# STM32F103ZGT7 register map
File version: 1.0
Registers are 32-bit, access not given, reset 0x0 unless marked. A register's access mark holds for its fields unless they carry their own. Offsets are from the block's base; [hi:lo] are bit positions; {n}, {i} and the like mark numbered series; 'fields as' and 'values as' point back to an identical list.

## RCC
Base 0x40021000
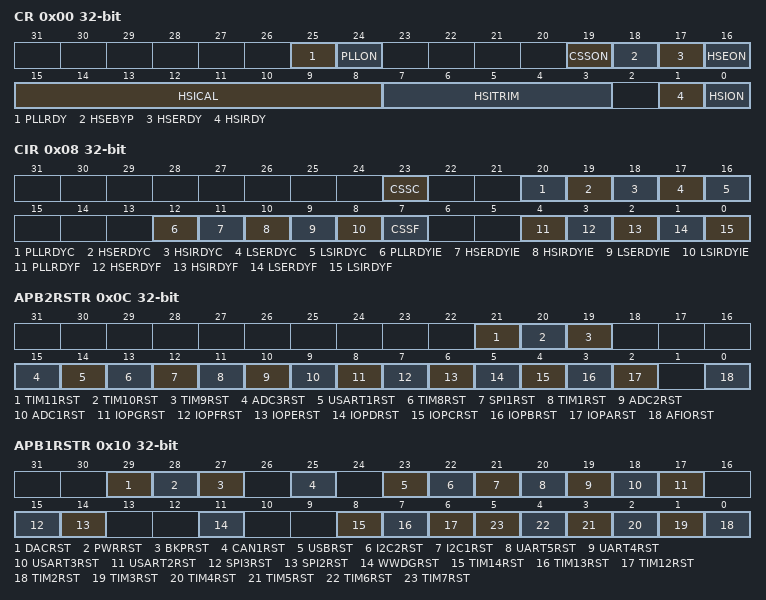
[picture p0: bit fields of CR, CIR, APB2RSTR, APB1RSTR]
0x00 CR
  [25] PLLRDY, [24] PLLON, [19] CSSON, [18] HSEBYP, [17] HSERDY, [16] HSEON, [15:8] HSICAL, [7:3] HSITRIM, [1] HSIRDY, [0] HSION
0x04 CFGR
  [26:24] MCO, [22] USBPRE, [21] PLLMULL10, [20] PLLMULL6, [20:19] PLLMULL8, [20:18] PLLMULL9, [17] PLLXTPRE, [16] PLLSRC, [15:14] ADCPRE, [13:11] PPRE2, [10:8] PPRE1, [7:4] HPRE, [3:2] SWS, [1:0] SW
0x08 CIR
  [23] CSSC, [20] PLLRDYC, [19] HSERDYC, [18] HSIRDYC, [17] LSERDYC, [16] LSIRDYC, [12] PLLRDYIE, [11] HSERDYIE, [10] HSIRDYIE, [9] LSERDYIE, [8] LSIRDYIE, [7] CSSF, [4] PLLRDYF, [3] HSERDYF, [2] HSIRDYF, [1] LSERDYF, [0] LSIRDYF
0x0C APB2RSTR
  [21] TIM11RST, [20] TIM10RST, [19] TIM9RST, [15] ADC3RST, [14] USART1RST, [13] TIM8RST, [12] SPI1RST, [11] TIM1RST, [10] ADC2RST, [9] ADC1RST, [8] IOPGRST, [7] IOPFRST, [6] IOPERST, [5] IOPDRST, [4] IOPCRST, [3] IOPBRST, [2] IOPARST, [0] AFIORST
0x10 APB1RSTR
  [29] DACRST, [28] PWRRST, [27] BKPRST, [25] CAN1RST, [23] USBRST, [22] I2C2RST, [21] I2C1RST, [20] UART5RST, [19] UART4RST, [18] USART3RST, [17] USART2RST, [15] SPI3RST, [14] SPI2RST, [11] WWDGRST, [8] TIM14RST, [7] TIM13RST, [6] TIM12RST, [n-2] TIM{n}RST (n=2..7)
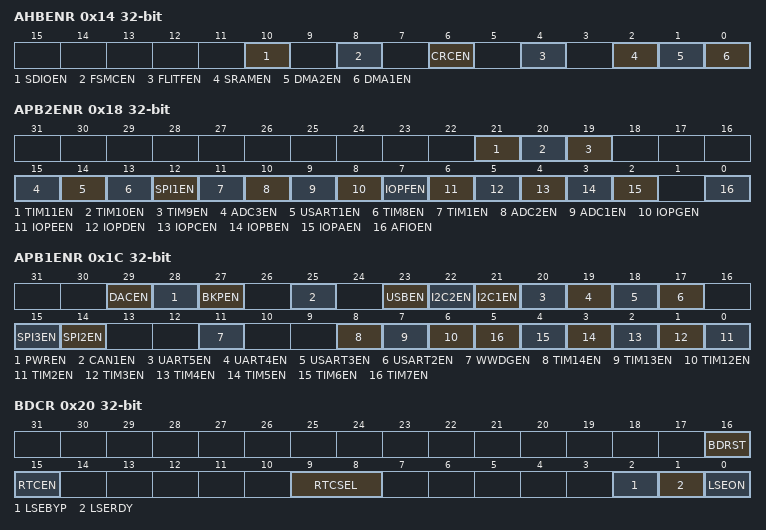
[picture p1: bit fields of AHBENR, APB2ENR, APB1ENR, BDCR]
0x14 AHBENR
  [10] SDIOEN, [8] FSMCEN, [6] CRCEN, [4] FLITFEN, [2] SRAMEN, [1] DMA2EN, [0] DMA1EN
0x18 APB2ENR
  [21] TIM11EN, [20] TIM10EN, [19] TIM9EN, [15] ADC3EN, [14] USART1EN, [13] TIM8EN, [12] SPI1EN, [11] TIM1EN, [10] ADC2EN, [9] ADC1EN, [8] IOPGEN, [7] IOPFEN, [6] IOPEEN, [5] IOPDEN, [4] IOPCEN, [3] IOPBEN, [2] IOPAEN, [0] AFIOEN
0x1C APB1ENR
  [29] DACEN, [28] PWREN, [27] BKPEN, [25] CAN1EN, [23] USBEN, [22] I2C2EN, [21] I2C1EN, [20] UART5EN, [19] UART4EN, [18] USART3EN, [17] USART2EN, [15] SPI3EN, [14] SPI2EN, [11] WWDGEN, [8] TIM14EN, [7] TIM13EN, [6] TIM12EN, [n-2] TIM{n}EN (n=2..7)
0x20 BDCR
  [16] BDRST, [15] RTCEN, [9:8] RTCSEL, [2] LSEBYP, [1] LSERDY, [0] LSEON
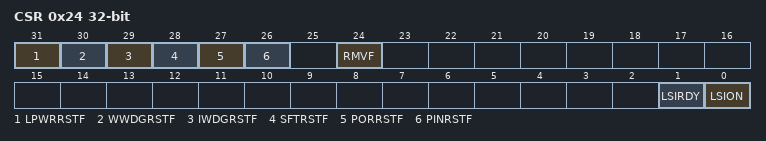
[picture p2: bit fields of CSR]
0x24 CSR
  [31] LPWRRSTF, [30] WWDGRSTF, [29] IWDGRSTF, [28] SFTRSTF, [27] PORRSTF, [26] PINRSTF, [24] RMVF, [1] LSIRDY, [0] LSION

## FLASH
Base 0x40022000
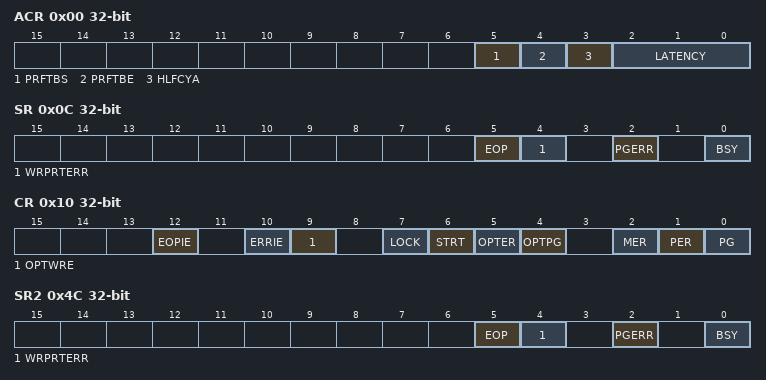
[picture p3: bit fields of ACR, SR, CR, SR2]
0x00 ACR
  [5] PRFTBS, [4] PRFTBE, [3] HLFCYA, [2:0] LATENCY
0x04 KEYR
  [31:0] FKEYR
0x08 OPTKEYR
  [31:0] OPTKEYR2
0x0C SR
  [5] EOP, [4] WRPRTERR, [2] PGERR, [0] BSY
0x10 CR
  [12] EOPIE, [10] ERRIE, [9] OPTWRE, [7] LOCK, [6] STRT, [5] OPTER, [4] OPTPG, [2] MER, [1] PER, [0] PG
0x14 AR
  [31:0] FAR2
0x1C OBR
  [25:18] DATA1, [17:10] DATA0, [5] BFB2, [4] nRST_STDBY, [3] nRST_STOP, [5:2] USER, [1] RDPRT, [0] OPTERR
0x20 WRPR
  [31:0] WRP
0x44 KEYR2
0x4C SR2
  [5] EOP, [4] WRPRTERR, [2] PGERR, [0] BSY
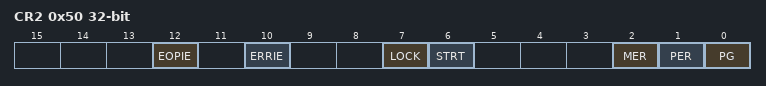
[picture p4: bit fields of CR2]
0x50 CR2
  [12] EOPIE, [10] ERRIE, [7] LOCK, [6] STRT, [2] MER, [1] PER, [0] PG
0x54 AR2

## CRC
Base 0x40023000
0x00 DR
0x04 IDR 8-bit
0x08 CR
  [0] RESET

## FSMC_Bank1
Base 0xA0000000
0x00 BTCR.0
  [29:28] ACCMOD, [27:24] DATLAT, [23:20] CLKDIV, [19] CBURSTRW, [19:16] BUSTURN, [15] ASYNCWAIT, [14] EXTMOD, [13] WAITEN, [12] WREN, [11] WAITCFG, [10] WRAPMOD, [9] WAITPOL, [15:8] DATAST, [6] FACCEN, [5:4] MWID, [3:2] MTYP, [1] MUXEN, [0] MBKEN
0x04 BTCR.1
  fields as BTCR.0
0x08 BTCR.2
  fields as BTCR.0
0x0C BTCR.3
  fields as BTCR.0
0x10 BTCR.4
  fields as BTCR.0
0x14 BTCR.5
  fields as BTCR.0
0x18 BTCR.6
  fields as BTCR.0
0x1C BTCR.7
  fields as BTCR.0

## FSMC_Bank2_3
Base 0xA0000060
0x00 PCR2
0x04 SR2
0x08 PMEM2
0x0C PATT2
0x14 ECCR2
  [31:0] ECC2
0x20 PCR3
0x24 SR3
0x28 PMEM3
0x2C PATT3
0x34 ECCR3
  [31:0] ECC3

## FSMC_Bank4
Base 0xA00000A0
0x00 PCR4
0x04 SR4
0x08 PMEM4
0x0C PATT4
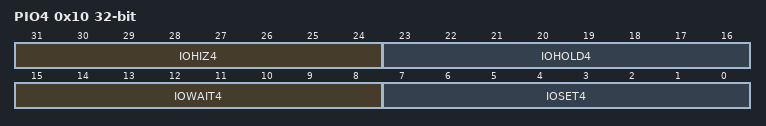
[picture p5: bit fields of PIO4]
0x10 PIO4
  [31:24] IOHIZ4, [23:16] IOHOLD4, [15:8] IOWAIT4, [7:0] IOSET4

## FSMC_Bank1E
Base 0xA0000104
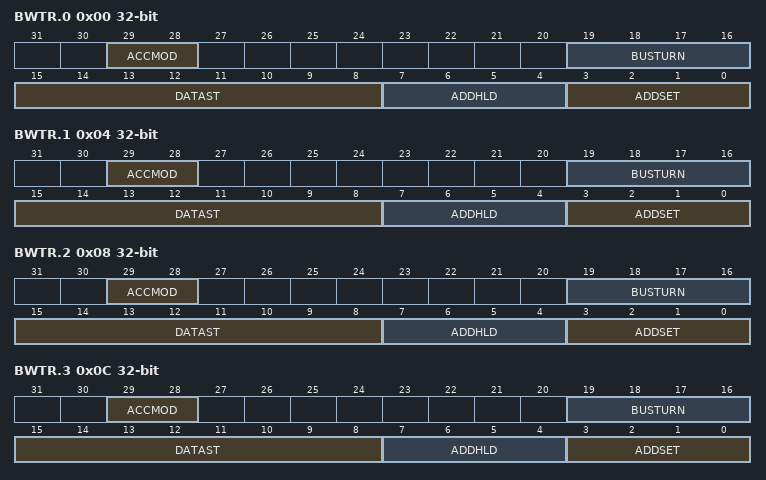
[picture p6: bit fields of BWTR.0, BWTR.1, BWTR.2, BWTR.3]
0x00 BWTR.0
  [29:28] ACCMOD, [19:16] BUSTURN, [15:8] DATAST, [7:4] ADDHLD, [3:0] ADDSET
0x04 BWTR.1
  fields as BWTR.0
0x08 BWTR.2
  fields as BWTR.0
0x0C BWTR.3
  fields as BWTR.0
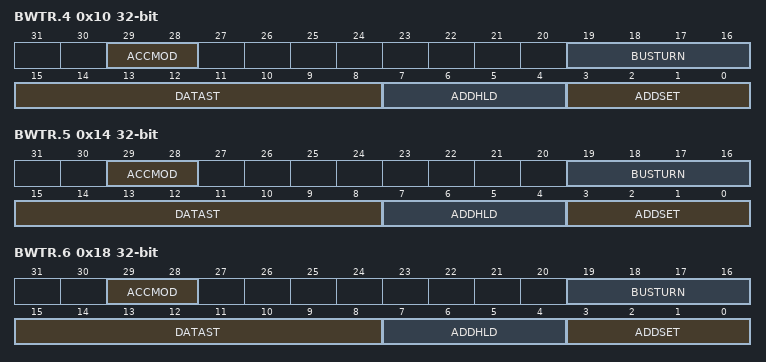
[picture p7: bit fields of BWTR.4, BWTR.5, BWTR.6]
0x10 BWTR.4
  fields as BWTR.0
0x14 BWTR.5
  fields as BWTR.0
0x18 BWTR.6
  fields as BWTR.0

## DBGMCU
Base 0xE0042000
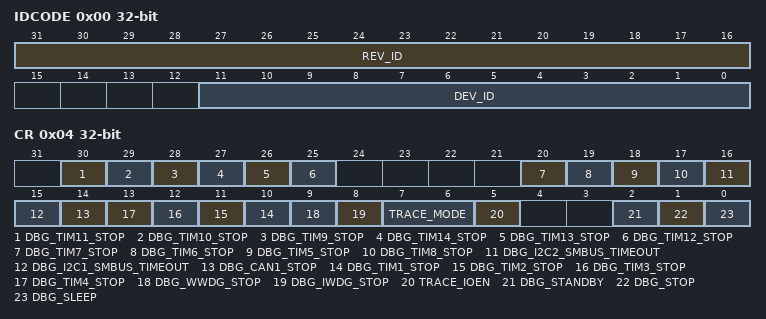
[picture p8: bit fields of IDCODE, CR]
0x00 IDCODE
  [31:16] REV_ID, [11:0] DEV_ID
0x04 CR
  [30] DBG_TIM11_STOP, [29] DBG_TIM10_STOP, [28] DBG_TIM9_STOP, [27] DBG_TIM14_STOP, [26] DBG_TIM13_STOP, [25] DBG_TIM12_STOP, [20] DBG_TIM7_STOP, [19] DBG_TIM6_STOP, [18] DBG_TIM5_STOP, [17] DBG_TIM8_STOP, [16] DBG_I2C2_SMBUS_TIMEOUT, [15] DBG_I2C1_SMBUS_TIMEOUT, [14] DBG_CAN1_STOP, [n+9] DBG_TIM{n}_STOP (n=1..4), [9] DBG_WWDG_STOP, [8] DBG_IWDG_STOP, [7:6] TRACE_MODE, [5] TRACE_IOEN, [2] DBG_STANDBY, [1] DBG_STOP, [0] DBG_SLEEP
